VERSION "2021.24.4"

NS_ :

BS_:

BU_: VEH CH Receiver X

BA_DEF_ BO_ "GenMsgSendType" ENUM "Cyclic";
BA_DEF_ BO_ "GenMsgCycleTime" INT 0 10000;

BA_ "GenMsgSendType" BO_ 528 0;
BA_ "GenMsgCycleTime" BO_ 528 100;

BA_ "GenMsgSendType" BO_ 802 0;
BA_ "GenMsgCycleTime" BO_ 802 1000;

BA_ "GenMsgSendType" BO_ 12 0;
BA_ "GenMsgCycleTime" BO_ 12 1000;

BO_ 2007 DI_debug_7D7: 8 Vector__XXX
 SG_ DI_brakeSwitchNC m32 : 63|1@1+ (1,0) [0|0] "" Vector__XXX
 SG_ DI_immobilizerCondition m65 : 63|1@1+ (1,0) [0|0] "" Vector__XXX
 SG_ DI_brakeSwitchNO m32 : 62|1@1+ (1,0) [0|0] "" Vector__XXX
 SG_ DI_ONE_isRollingBackward m35 : 59|1@1+ (1,0) [0|0] "" Vector__XXX
 SG_ DI_ONE_quickBrakeBlendRequested m35 : 58|1@1+ (1,0) [0|0] "" Vector__XXX
 SG_ DI_ONE_slowBrakeBlendRequested m35 : 57|1@1+ (1,0) [0|0] "" Vector__XXX
 SG_ DI_ONE_vehicleHoldRequested m35 : 56|1@1+ (1,0) [0|0] "" Vector__XXX
 SG_ DI_immobilizerStack m68 : 56|8@1+ (0.4,0) [0|0] "" Vector__XXX
 SG_ DI_ssmState m32 : 56|4@1+ (1,0) [0|0] "" Vector__XXX
 SG_ DI_locCheckSpeedRef m75 : 54|8@1+ (1,0) [0|0] "" Vector__XXX
 SG_ DI_aebBlendOutActive m45 : 50|1@1+ (1,0) [0|0] "" Vector__XXX
 SG_ DI_ONE_ui m36 : 48|16@1- (0.5,0) [0|0] "" Vector__XXX
 SG_ DI_PED_zeroPedalTorque m38 : 48|16@1- (0.5,0) [0|0] "" Vector__XXX
 SG_ DI_module10HzStack m66 : 48|8@1+ (0.4,0) [0|0] "" Vector__XXX
 SG_ DI_pwrSatChargeCurrent m32 : 48|8@1+ (0.4,0) [0|0] "" Vector__XXX
 SG_ DI_tqScaleShift m33 : 48|8@1+ (0.4,0) [0|0] "" Vector__XXX
 SG_ DI_xcpStack m68 : 48|8@1+ (0.4,0) [0|0] "" Vector__XXX
 SG_ DI_brkStState m45 : 45|3@1+ (1,0) [0|0] "" Vector__XXX
 SG_ DI_ONE_zeroSpeedTorqueFwd m35 : 40|16@1- (0.5,0) [0|0] "" Vector__XXX
 SG_ DI_controlStack m67 : 40|8@1+ (0.4,0) [0|0] "" Vector__XXX
 SG_ DI_cpu10msMin m66 : 40|8@1+ (0.4,0) [0|0] "" Vector__XXX
 SG_ DI_opdUnavailableReason m45 : 40|5@1+ (1,0) [0|0] "" Vector__XXX
 SG_ DI_pwrSatDischargeCurrent m32 : 40|8@1+ (0.4,0) [0|0] "" Vector__XXX
 SG_ DI_sysStateExitCondition m34 : 40|5@1+ (1,0) [0|0] "" Vector__XXX
 SG_ DI_systemTorqueCommand m53 : 40|16@1- (0.5,0) [0|0] "" Vector__XXX
 SG_ DI_tqSatUiRegenTorque m33 : 40|8@1+ (0.4,0) [0|0] "" Vector__XXX
 SG_ DI_udsStack m68 : 40|8@1+ (0.4,0) [0|0] "" Vector__XXX
 SG_ DI_ONE_feedbackSpeedFilt m37 : 32|13@1+ (0.08,-40) [0|0] "" Vector__XXX
 SG_ DI_ONE_up m36 : 32|16@1- (0.5,0) [0|0] "" Vector__XXX
 SG_ DI_PED_noCruiseCommandPed m38 : 32|16@1- (0.5,0) [0|0] "" Vector__XXX
 SG_ DI_aebCancelReason m45 : 32|8@1+ (1,0) [0|0] "" Vector__XXX
 SG_ DI_cpu100HzAvg m66 : 32|8@1+ (0.4,0) [0|0] "" Vector__XXX
 SG_ DI_cpu20kHzAvg m67 : 32|8@1+ (0.4,0) [0|0] "" Vector__XXX
 SG_ DI_eepromStack m68 : 32|8@1+ (0.4,0) [0|0] "" Vector__XXX
 SG_ DI_pedalPosFilt m2 : 32|8@1+ (0.4,0) [0|0] "" Vector__XXX
 SG_ DI_pwrSatMinBusVoltage m32 : 32|8@1+ (0.4,0) [0|0] "" Vector__XXX
 SG_ DI_tqSatUiDriveTorque m33 : 32|8@1+ (0.4,0) [0|0] "" Vector__XXX
 SG_ DI_regenBackfillAbsSatState m39 : 26|2@1+ (1,0) [0|0] "" Vector__XXX
 SG_ DI_ONE_zeroPedalTorqueFwd m35 : 24|16@1- (0.5,0) [0|0] "" Vector__XXX
 SG_ DI_aebUnavailableReason m45 : 24|4@1+ (1,0) [0|0] "" Vector__XXX
 SG_ DI_cpu100HzMin m66 : 24|8@1+ (0.4,0) [0|0] "" Vector__XXX
 SG_ DI_cpu20kHzMin m67 : 24|8@1+ (0.4,0) [0|0] "" Vector__XXX
 SG_ DI_decodeHardwareStack m68 : 24|8@1+ (0.4,0) [0|0] "" Vector__XXX
 SG_ DI_pwrSatMaxBusVoltage m32 : 24|8@1+ (0.4,0) [0|0] "" Vector__XXX
 SG_ DI_sysPedalMaxTorque m34 : 24|15@1+ (0.5,0) [0|0] "" Vector__XXX
 SG_ DI_sysPostPedalMaxTorque m53 : 24|15@1+ (0.5,0) [0|0] "" Vector__XXX
 SG_ DI_regenBackfillUnavailableReaso m39 : 21|5@1+ (1,0) [0|0] "" Vector__XXX
 SG_ DI_veResForce m33 : 20|12@1- (0.0005,0) [0|0] "" Vector__XXX
 SG_ DI_ONE_feedbackTorquePed m36 : 16|16@1- (0.5,0) [0|0] "" Vector__XXX
 SG_ DI_ONE_targetSpeedFilt m37 : 16|13@1+ (0.08,-40) [0|0] "" Vector__XXX
 SG_ DI_PED_pedalTorqueFwd m38 : 16|16@1- (0.5,0) [0|0] "" Vector__XXX
 SG_ DI_aebFaultReason m45 : 16|4@1+ (1,0) [0|0] "" Vector__XXX
 SG_ DI_brakeCommandScale m2 : 16|9@1+ (0.02,0) [0|0] "" Vector__XXX
 SG_ DI_cpu10HzAvg m66 : 16|8@1+ (0.4,0) [0|0] "" Vector__XXX
 SG_ DI_cpu1kHzAvg m67 : 16|8@1+ (0.4,0) [0|0] "" Vector__XXX
 SG_ DI_idleStack m68 : 16|8@1+ (0.4,0) [0|0] "" Vector__XXX
 SG_ DI_pwrSatMaxRegenPower m32 : 16|8@1+ (0.4,0) [0|0] "" Vector__XXX
 SG_ DI_ONE_onePedalCommandFwd m35 : 8|16@1- (0.5,0) [0|0] "" Vector__XXX
 SG_ DI_cpu10HzMin m66 : 8|8@1+ (0.4,0) [0|0] "" Vector__XXX
 SG_ DI_cpu1kHzMin m67 : 8|8@1+ (0.4,0) [0|0] "" Vector__XXX
 SG_ DI_muSurfHigh m2 : 8|8@1+ (0.005,0) [0|0] "" Vector__XXX
 SG_ DI_pwrSatMaxDischargePower m32 : 8|8@1+ (0.4,0) [0|0] "" Vector__XXX
 SG_ DI_regenBackfillCmd m39 : 8|13@1+ (2,0) [0|0] "" Vector__XXX
 SG_ DI_sysHeatPowerOptimal m50 : 8|8@1+ (0.08,0) [0|0] "" Vector__XXX
 SG_ DI_sysPedalMinTorque m34 : 8|15@1+ (0.5,-13000) [0|0] "" Vector__XXX
 SG_ DI_sysPostPedalMinTorque m53 : 8|15@1+ (0.5,-13000) [0|0] "" Vector__XXX
 SG_ DI_systemStack m68 : 8|8@1+ (0.4,0) [0|0] "" Vector__XXX
 SG_ DI_veMassInvRaw m33 : 8|12@1+ (1e-07,0.0001) [0|0] "" Vector__XXX
 SG_ DI_debugSelector M : 0|8@1+ (1,0) [0|0] "" Vector__XXX

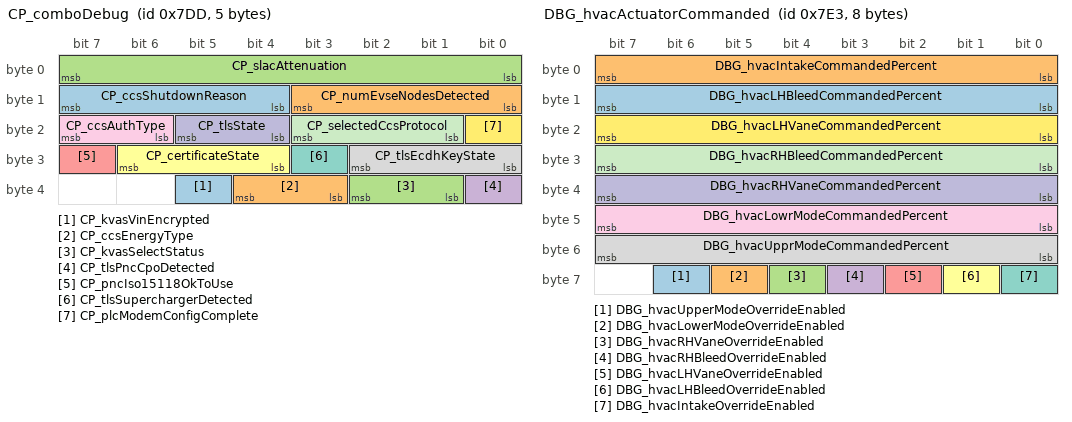
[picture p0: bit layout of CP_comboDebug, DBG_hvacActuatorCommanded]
BO_ 2013 CP_comboDebug: 5 Vector__XXX
 SG_ CP_kvasVinEncrypted : 37|1@1+ (1,0) [0|0] "" Vector__XXX
 SG_ CP_ccsEnergyType : 35|2@1+ (1,0) [0|0] "" Vector__XXX
 SG_ CP_kvasSelectStatus : 33|2@1+ (1,0) [0|0] "" Vector__XXX
 SG_ CP_tlsPncCpoDetected : 32|1@1+ (1,0) [0|0] "" Vector__XXX
 SG_ CP_pncIso15118OkToUse : 31|1@1+ (1,0) [0|0] "" Vector__XXX
 SG_ CP_certificateState : 28|3@1+ (1,0) [0|0] "" Vector__XXX
 SG_ CP_tlsSuperchargerDetected : 27|1@1+ (1,0) [0|0] "" Vector__XXX
 SG_ CP_tlsEcdhKeyState : 24|3@1+ (1,0) [0|0] "" Vector__XXX
 SG_ CP_ccsAuthType : 22|2@1+ (1,0) [0|0] "" Vector__XXX
 SG_ CP_tlsState : 20|2@1+ (1,0) [0|0] "" Vector__XXX
 SG_ CP_selectedCcsProtocol : 17|3@1+ (1,0) [0|0] "" Vector__XXX
 SG_ CP_plcModemConfigComplete : 16|1@1+ (1,0) [0|0] "" Vector__XXX
 SG_ CP_ccsShutdownReason : 12|4@1+ (1,0) [0|0] "" Vector__XXX
 SG_ CP_numEvseNodesDetected : 8|4@1+ (1,0) [0|0] "" Vector__XXX
 SG_ CP_slacAttenuation : 0|8@1+ (1,0) [0|0] "" Vector__XXX

BO_ 2014 UDS_functionalRequest_CH: 12 Vector__XXX
 SG_ UDS_functionalRequestDataCH : 7|64@0+ (1,0) [0|0] "" Vector__XXX

BO_ 2015 UDS_functionalRequest: 12 Vector__XXX
 SG_ UDS_functionalRequestData_7 : 63|8@0+ (1,0) [0|0] "" Vector__XXX
 SG_ UDS_functionalRequestData_6 : 55|8@0+ (1,0) [0|0] "" Vector__XXX
 SG_ UDS_functionalRequestData_5 : 47|8@0+ (1,0) [0|0] "" Vector__XXX
 SG_ UDS_functionalRequestData_4 : 39|8@0+ (1,0) [0|0] "" Vector__XXX
 SG_ UDS_functionalRequestData_3 : 31|8@0+ (1,0) [0|0] "" Vector__XXX
 SG_ UDS_functionalRequestData_2 : 23|8@0+ (1,0) [0|0] "" Vector__XXX
 SG_ UDS_functionalRequestData_1 : 15|8@0+ (1,0) [0|0] "" Vector__XXX
 SG_ UDS_functionalRequestData_0 : 7|8@0+ (1,0) [0|0] "" Vector__XXX

BO_ 2019 DBG_hvacActuatorCommanded: 8 Vector__XXX
 SG_ DBG_hvacUpperModeOverrideEnabled : 62|1@1+ (1,0) [0|0] "" Vector__XXX
 SG_ DBG_hvacLowerModeOverrideEnabled : 61|1@1+ (1,0) [0|0] "" Vector__XXX
 SG_ DBG_hvacRHVaneOverrideEnabled : 60|1@1+ (1,0) [0|0] "" Vector__XXX
 SG_ DBG_hvacRHBleedOverrideEnabled : 59|1@1+ (1,0) [0|0] "" Vector__XXX
 SG_ DBG_hvacLHVaneOverrideEnabled : 58|1@1+ (1,0) [0|0] "" Vector__XXX
 SG_ DBG_hvacLHBleedOverrideEnabled : 57|1@1+ (1,0) [0|0] "" Vector__XXX
 SG_ DBG_hvacIntakeOverrideEnabled : 56|1@1+ (1,0) [0|0] "" Vector__XXX
 SG_ DBG_hvacUpprModeCommandedPercent : 48|8@1+ (0.4,0) [0|0] "" Vector__XXX
 SG_ DBG_hvacLowrModeCommandedPercent : 40|8@1+ (0.4,0) [0|0] "" Vector__XXX
 SG_ DBG_hvacRHVaneCommandedPercent : 32|8@1+ (0.4,0) [0|0] "" Vector__XXX
 SG_ DBG_hvacRHBleedCommandedPercent : 24|8@1+ (0.4,0) [0|0] "" Vector__XXX
 SG_ DBG_hvacLHVaneCommandedPercent : 16|8@1+ (0.4,0) [0|0] "" Vector__XXX
 SG_ DBG_hvacLHBleedCommandedPercent : 8|8@1+ (0.4,0) [0|0] "" Vector__XXX
 SG_ DBG_hvacIntakeCommandedPercent : 0|8@1+ (0.4,0) [0|0] "" Vector__XXX

BO_ 2021 DIR_dlogData: 8 Vector__XXX
 SG_ DIR_dlogData : 0|64@1+ (1,0) [0|0] "" Vector__XXX

BO_ 2031 DBG_testMessage: 8 Vector__XXX
 SG_ DBG_testID : 0|16@1+ (1,0) [0|0] "" Vector__XXX

BO_ 2034 BMS_debugInfo_10Hz: 8 Vector__XXX
 SG_ BMS_verResourceRequest m29 : 58|2@1+ (1,0) [0|0] "" Vector__XXX
 SG_ BMS_bmsResourceRequest m29 : 56|2@1+ (1,0) [0|0] "" Vector__XXX
 SG_ BMS_dbgResistanceScaleChg m28 : 56|8@1+ (0.02,0) [0|0] "" Vector__XXX
 SG_ BMS_dbgResistanceScaleDch m27 : 56|8@1+ (0.02,0) [0|0] "" Vector__XXX
 SG_ BMS_cacUpdateError m18 : 54|9@1+ (0.2,0) [0|0] "" Vector__XXX
 SG_ BMS_hvpResourceRequest m29 : 54|2@1+ (1,0) [0|0] "" Vector__XXX
 SG_ BMS_refPointCacError2 m17 : 53|9@1+ (0.2,0) [0|0] "" Vector__XXX
 SG_ BMS_cacUpdateEndPoint m18 : 52|2@1+ (1,0) [0|0] "" Vector__XXX
 SG_ BMS_cpResourceRequest m29 : 52|2@1+ (1,0) [0|0] "" Vector__XXX
 SG_ BMS_cacUpdateStartPoint m18 : 50|2@1+ (1,0) [0|0] "" Vector__XXX
 SG_ BMS_ocvEstBrick1 m32 : 50|12@1+ (0.002,0) [0|0] "" Vector__XXX
 SG_ BMS_vehBusResourceRequest m29 : 50|2@1+ (1,0) [0|0] "" Vector__XXX
 SG_ BMS_hvsBusResourceRequest m29 : 48|2@1+ (1,0) [0|0] "" Vector__XXX
 SG_ BMS_cacUpdateCounter m18 : 47|3@1+ (1,0) [0|0] "" Vector__XXX
 SG_ BMS_hviBusResourceRequest m29 : 46|2@1+ (1,0) [0|0] "" Vector__XXX
 SG_ BMS_thmMdlDBG10 m13 : 46|10@1+ (0.1,-30) [0|0] "" Vector__XXX
 SG_ BMS_thmMdlDBG5 m12 : 46|10@1+ (0.1,-30) [0|0] "" Vector__XXX
 SG_ BMS_refPointCacError1 m17 : 44|9@1+ (0.2,0) [0|0] "" Vector__XXX
 SG_ BMS_sleepRequest m29 : 43|3@1+ (1,0) [0|0] "" Vector__XXX
 SG_ BMS_dbg1v5ReferenceHvp m21 : 40|16@1+ (0.001,0) [0|0] "" Vector__XXX
 SG_ BMS_dbgCapacitanceC2 m28 : 40|16@1+ (0.1,0) [0|0] "" Vector__XXX
 SG_ BMS_dbgCpFaultInputV m22 : 40|16@1+ (0.001,0) [0|0] "" Vector__XXX
 SG_ BMS_dbgCpLatchEnableV m25 : 40|16@1+ (0.001,0) [0|0] "" Vector__XXX
 SG_ BMS_dbgDcLinkCtrSenseCurrent m23 : 40|16@1+ (0.01,0) [0|0] "" Vector__XXX
 SG_ BMS_dbgHvilCoverVSense m24 : 40|16@1+ (0.001,0) [0|0] "" Vector__XXX
 SG_ BMS_dbgMaxCurrentDischarge m26 : 40|14@1+ (0.15,0) [0|0] "" Vector__XXX
 SG_ BMS_dbgResistanceR1 m27 : 40|16@1+ (0.001,0) [0|0] "" Vector__XXX
 SG_ BMS_packPositiveV m15 : 40|16@1- (0.02,0) [0|0] "" Vector__XXX
 SG_ BMS_restTime1 m20 : 40|15@1+ (0.1,0) [0|0] "" Vector__XXX
 SG_ BMS_sleepState m29 : 40|3@1+ (1,0) [0|0] "" Vector__XXX
 SG_ BMS_socRestingCurrentThreshold m3 : 40|12@1+ (0.001,0) [0|0] "" Vector__XXX
 SG_ BMS_isResting m3 : 39|1@1+ (1,0) [0|0] "" Vector__XXX
 SG_ BMS_ocvMaxBrick1 m32 : 38|12@1+ (0.002,0) [0|0] "" Vector__XXX
 SG_ BMS_cacInitialPtSocByOcv m18 : 37|10@1+ (0.1,0) [0|0] "" Vector__XXX
 SG_ BMS_thmMdlDBG4 m12 : 36|10@1+ (0.1,-30) [0|0] "" Vector__XXX
 SG_ BMS_thmMdlDBG9 m13 : 36|10@1+ (0.1,-30) [0|0] "" Vector__XXX
 SG_ BMS_refPointDeltaAhError m17 : 35|9@1- (0.05,0) [0|0] "" Vector__XXX
 SG_ BMS_verResourceState m29 : 35|3@1+ (1,0) [0|0] "" Vector__XXX
 SG_ BMS_ahDischarge m1 : 32|24@1+ (0.1,0) [0|0] "" Vector__XXX
 SG_ BMS_bmsResourceState m29 : 32|3@1+ (1,0) [0|0] "" Vector__XXX
 SG_ BMS_dbgBrick1OcvAccuracyBuffer m33 : 32|13@1+ (0.01,0) [0|0] "" Vector__XXX
 SG_ BMS_minBrickOcvIndex m3 : 32|7@1+ (1,0) [0|0] "" Vector__XXX
 SG_ BMS_cacEstimateBrick1 m18 : 27|10@1+ (0.5,75) [0|0] "" Vector__XXX
 SG_ BMS_pcsResourceState m29 : 27|3@1+ (1,0) [0|0] "" Vector__XXX
 SG_ BMS_dbgSocByOcvEst m16 : 26|10@1+ (0.1,0) [0|0] "" Vector__XXX
 SG_ BMS_ocvMinBrick1 m32 : 26|12@1+ (0.002,0) [0|0] "" Vector__XXX
 SG_ BMS_thmMdlDBG13 m14 : 26|10@1+ (0.1,-30) [0|0] "" Vector__XXX
 SG_ BMS_thmMdlDBG3 m12 : 26|10@1+ (0.1,-30) [0|0] "" Vector__XXX
 SG_ BMS_thmMdlDBG8 m13 : 26|10@1+ (0.1,-30) [0|0] "" Vector__XXX
 SG_ BMS_dbgStandbySupplyGood m30 : 25|1@1+ (1,0) [0|0] "" Vector__XXX
 SG_ BMS_dbg3v0ReferenceHvp m21 : 24|16@1+ (0.001,0) [0|0] "" Vector__XXX
 SG_ BMS_dbgCapacitanceC1 m28 : 24|16@1+ (0.1,0) [0|0] "" Vector__XXX
 SG_ BMS_dbgCpNegativeV m22 : 24|16@1- (0.02,0) [0|0] "" Vector__XXX
 SG_ BMS_dbgDcLinkNegativeV m23 : 24|16@1- (0.02,0) [0|0] "" Vector__XXX
 SG_ BMS_dbgFloodPortV2 m25 : 24|16@1+ (0.001,0) [0|0] "" Vector__XXX
 SG_ BMS_dbgInternalHvilSenseV m24 : 24|16@1+ (0.001,0) [0|0] "" Vector__XXX
 SG_ BMS_dbgMinLoadedVoltageDischarge m26 : 24|16@1+ (0.0001,0) [0|0] "" Vector__XXX
 SG_ BMS_dbgPolarizationVoltageV2 m27 : 24|16@1- (0.0001,0) [0|0] "" Vector__XXX
 SG_ BMS_dbgStandbySupplyEnabled m30 : 24|1@1+ (1,0) [0|0] "" Vector__XXX
 SG_ BMS_hvpResourceState m29 : 24|3@1+ (1,0) [0|0] "" Vector__XXX
 SG_ BMS_packNegativeV m15 : 24|16@1- (0.02,0) [0|0] "" Vector__XXX
 SG_ BMS_refPointDeltaAh m17 : 24|11@1- (0.5,0) [0|0] "" Vector__XXX
 SG_ BMS_stdCacError m19 : 24|8@1+ (0.2,0) [0|0] "" Vector__XXX
 SG_ BMS_stopSecondsElapsed m20 : 24|16@1+ (1,0) [0|0] "" Vector__XXX
 SG_ BMS_agedDischargePolarization m33 : 20|12@1+ (0.002,0) [0|0] "" Vector__XXX
 SG_ BMS_minBrickOcvMin m3 : 20|12@1+ (0.002,0) [0|0] "" Vector__XXX
 SG_ BMS_posIsolationSensorState m2 : 20|1@1+ (1,0) [0|0] "" Vector__XXX
 SG_ BMS_cacNetAhError m18 : 19|8@1+ (0.1,0) [0|0] "" Vector__XXX
 SG_ BMS_cpResourceState m29 : 19|3@1+ (1,0) [0|0] "" Vector__XXX
 SG_ BMS_maxSocByAhRawBrickId m32 : 19|7@1+ (1,1) [0|0] "" Vector__XXX
 SG_ BMS_negIsolationSensorState m2 : 19|1@1+ (1,0) [0|0] "" Vector__XXX
 SG_ BMS_dbgSocByOcvMin m16 : 16|10@1+ (0.1,0) [0|0] "" Vector__XXX
 SG_ BMS_positiveRIsoState m2 : 16|3@1+ (1,0) [0|0] "" Vector__XXX
 SG_ BMS_thmMdlDBG12 m14 : 16|10@1+ (0.1,-30) [0|0] "" Vector__XXX
 SG_ BMS_thmMdlDBG2 m12 : 16|10@1+ (0.1,-30) [0|0] "" Vector__XXX
 SG_ BMS_thmMdlDBG7 m13 : 16|10@1+ (0.1,-30) [0|0] "" Vector__XXX
 SG_ BMS_vehBusResourceState m29 : 16|3@1+ (1,0) [0|0] "" Vector__XXX
 SG_ BMS_refPointDeltaSoc m17 : 14|10@1+ (0.1,0) [0|0] "" Vector__XXX
 SG_ BMS_candidate2CacPointValid m17 : 13|1@1+ (1,0) [0|0] "" Vector__XXX
 SG_ BMS_candidate1CacPointValid m17 : 12|1@1+ (1,0) [0|0] "" Vector__XXX
 SG_ BMS_hvsBusResourceState m29 : 11|3@1+ (1,0) [0|0] "" Vector__XXX
 SG_ BMS_impedanceDevState m0 : 11|2@1+ (1,0) [0|0] "" Vector__XXX
 SG_ BMS_initialCacPointValid m17 : 11|1@1+ (1,0) [0|0] "" Vector__XXX
 SG_ BMS_negativeRIsoState m2 : 11|3@1+ (1,0) [0|0] "" Vector__XXX
 SG_ BMS_cacActivePoint m17 : 9|2@1+ (1,0) [0|0] "" Vector__XXX
 SG_ BMS_agedChargePolarization m33 : 8|12@1+ (0.002,0) [0|0] "" Vector__XXX
 SG_ BMS_ahCharge m1 : 8|24@1+ (0.1,0) [0|0] "" Vector__XXX
 SG_ BMS_avgCacError m19 : 8|9@1+ (0.2,0) [0|0] "" Vector__XXX
 SG_ BMS_brickRestingForCac m17 : 8|1@1+ (1,0) [0|0] "" Vector__XXX
 SG_ BMS_cacNetAhCounter m18 : 8|11@1- (1,0) [0|0] "" Vector__XXX
 SG_ BMS_dbg3v0ReferenceBms m21 : 8|16@1+ (0.001,0) [0|0] "" Vector__XXX
 SG_ BMS_dbgCpPositiveV m22 : 8|16@1- (0.02,0) [0|0] "" Vector__XXX
 SG_ BMS_dbgDcLinkPositiveV m23 : 8|16@1- (0.02,0) [0|0] "" Vector__XXX
 SG_ BMS_dbgFloodPortV1 m25 : 8|16@1+ (0.001,0) [0|0] "" Vector__XXX
 SG_ BMS_dbgMaxLoadedVoltageDischarge m26 : 8|16@1+ (0.0001,0) [0|0] "" Vector__XXX
 SG_ BMS_dbgPolarizationVoltageV1 m27 : 8|16@1- (0.0001,0) [0|0] "" Vector__XXX
 SG_ BMS_dbgResistanceR2 m28 : 8|16@1+ (0.001,0) [0|0] "" Vector__XXX
 SG_ BMS_dbgStandbySupplyOutV m30 : 8|16@1+ (0.001,0) [0|0] "" Vector__XXX
 SG_ BMS_dbgVerSenseV m24 : 8|16@1+ (0.001,0) [0|0] "" Vector__XXX
 SG_ BMS_driveBrickVoltageTarget m31 : 8|10@1+ (0.01,0) [0|0] "" Vector__XXX
 SG_ BMS_faultRetryCount m0 : 8|3@1+ (1,0) [0|0] "" Vector__XXX
 SG_ BMS_hviBusResourceState m29 : 8|3@1+ (1,0) [0|0] "" Vector__XXX
 SG_ BMS_isolationMode m2 : 8|3@1+ (1,0) [0|0] "" Vector__XXX
 SG_ BMS_maxSocByAhRaw m32 : 8|11@1+ (0.1,0) [0|0] "" Vector__XXX
 SG_ BMS_minBrickOcvMax m3 : 8|12@1+ (0.002,0) [0|0] "" Vector__XXX
 SG_ BMS_sumBrickVoltages m15 : 8|15@1+ (0.02,0) [0|0] "" Vector__XXX
 SG_ BMS_dbgPcsIsActiveOnHvs m0 : 7|1@1+ (1,0) [0|0] "" Vector__XXX
 SG_ BMS_allBricksRestingForCac m17 : 6|1@1+ (1,0) [0|0] "" Vector__XXX
 SG_ BMS_dbgPcsReportedOn m0 : 6|1@1+ (1,0) [0|0] "" Vector__XXX
 SG_ BMS_dbgSocByOcvMax m16 : 6|10@1+ (0.1,0) [0|0] "" Vector__XXX
 SG_ BMS_thmMdlDBG1 m12 : 6|10@1+ (0.1,-30) [0|0] "" Vector__XXX
 SG_ BMS_thmMdlDBG11 m14 : 6|10@1+ (0.1,-30) [0|0] "" Vector__XXX
 SG_ BMS_thmMdlDBG6 m13 : 6|10@1+ (0.1,-30) [0|0] "" Vector__XXX
 SG_ BMS_vshTestNeededTimer m20 : 6|18@1+ (1,0) [0|0] "" Vector__XXX
 SG_ BMS_10HzDebug_Id M : 0|6@1+ (1,0) [0|0] "" Vector__XXX

BO_ 2036 GTW_canLogAvailability: 1 Vector__XXX
 SG_ GTW_canLogServiceAvailability : 0|2@1+ (1,0) [0|0] "" Vector__XXX

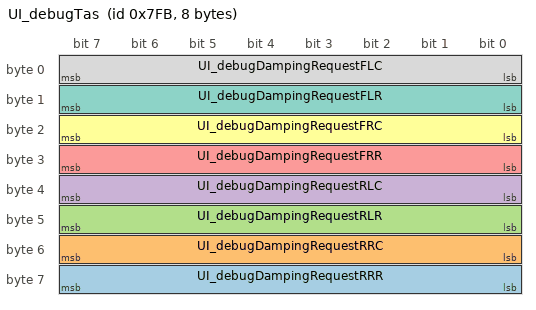
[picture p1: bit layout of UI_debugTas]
BO_ 2043 UI_debugTas: 8 Vector__XXX
 SG_ UI_debugDampingRequestRRR : 56|8@1+ (0.01,0) [0|0] "" Vector__XXX
 SG_ UI_debugDampingRequestRRC : 48|8@1+ (0.01,0) [0|0] "" Vector__XXX
 SG_ UI_debugDampingRequestRLR : 40|8@1+ (0.01,0) [0|0] "" Vector__XXX
 SG_ UI_debugDampingRequestRLC : 32|8@1+ (0.01,0) [0|0] "" Vector__XXX
 SG_ UI_debugDampingRequestFRR : 24|8@1+ (0.01,0) [0|0] "" Vector__XXX
 SG_ UI_debugDampingRequestFRC : 16|8@1+ (0.01,0) [0|0] "" Vector__XXX
 SG_ UI_debugDampingRequestFLR : 8|8@1+ (0.01,0) [0|0] "" Vector__XXX
 SG_ UI_debugDampingRequestFLC : 0|8@1+ (0.01,0) [0|0] "" Vector__XXX

BO_ 2046 PCS2_DRLog: 8 Vector__XXX
 SG_ PCS2_DRLog_CPU0_PlotId m1 : 48|8@1+ (1,0) [0|0] "" Vector__XXX
 SG_ PCS2_DRLog_CPU1_PlotId m11 : 48|8@1+ (1,0) [0|0] "" Vector__XXX
 SG_ PCS2_DRLog_CPU2_PlotId m21 : 48|8@1+ (1,0) [0|0] "" Vector__XXX
 SG_ PCS2_DRLog_CPU3_PlotId m31 : 48|8@1+ (1,0) [0|0] "" Vector__XXX
 SG_ PCS2_DRLog_CPU0_InstanceTriggerA m3 : 40|16@1+ (1,0) [0|0] "" Vector__XXX
 SG_ PCS2_DRLog_CPU1_InstanceTriggerA m13 : 40|16@1+ (1,0) [0|0] "" Vector__XXX
 SG_ PCS2_DRLog_CPU2_InstanceTriggerA m23 : 40|16@1+ (1,0) [0|0] "" Vector__XXX
 SG_ PCS2_DRLog_CPU3_InstanceTriggerA m33 : 40|16@1+ (1,0) [0|0] "" Vector__XXX
 SG_ PCS2_DRLog_CPU0_Sample m2 : 32|32@1- (0.001,0) [0|0] "" Vector__XXX
 SG_ PCS2_DRLog_CPU0_Sample_10V0_rail m170 : 32|32@1- (0.001,0) [0|0] "" Vector__XXX
 SG_ PCS2_DRLog_CPU0_Sample_18V0_LLC_ m118 : 32|32@1- (0.001,0) [0|0] "" Vector__XXX
 SG_ PCS2_DRLog_CPU0_Sample_18V0_Volt m117 : 32|32@1- (0.001,0) [0|0] "" Vector__XXX
 SG_ PCS2_DRLog_CPU0_Sample_18V0_boos m160 : 32|32@1- (0.001,0) [0|0] "" Vector__XXX
 SG_ PCS2_DRLog_CPU0_Sample_18V0_buck m169 : 32|32@1- (0.001,0) [0|0] "" Vector__XXX
 SG_ PCS2_DRLog_CPU0_Sample_1V6_ref_v m172 : 32|32@1- (0.001,0) [0|0] "" Vector__XXX
 SG_ PCS2_DRLog_CPU0_Sample_4V5_rail_ m171 : 32|32@1- (0.001,0) [0|0] "" Vector__XXX
 SG_ PCS2_DRLog_CPU0_Sample_boost_buc m174 : 32|32@1- (0.001,0) [0|0] "" Vector__XXX
 SG_ PCS2_DRLog_CPU0_Sample_boost_ise m173 : 32|32@1- (0.001,0) [0|0] "" Vector__XXX
 SG_ PCS2_DRLog_CPU0_Sample_boos_0000 m175 : 32|32@1- (0.001,0) [0|0] "" Vector__XXX
 SG_ PCS2_DRLog_CPU0_Sample_burst_mod m158 : 32|32@1- (0.001,0) [0|0] "" Vector__XXX
 SG_ PCS2_DRLog_CPU0_Sample_channel8 m119 : 32|32@1- (0.001,0) [0|0] "" Vector__XXX
 SG_ PCS2_DRLog_CPU0_Sample_dcdc_vHv m163 : 32|32@1- (0.001,0) [0|0] "" Vector__XXX
 SG_ PCS2_DRLog_CPU0_Sample_dcdc_vHv_ m116 : 32|32@1- (0.001,0) [0|0] "" Vector__XXX
 SG_ PCS2_DRLog_CPU0_Sample_dcdc_0000 m102 : 32|32@1- (0.001,0) [0|0] "" Vector__XXX
 SG_ PCS2_DRLog_CPU0_Sample_dcdc_vLv m103 : 32|32@1- (0.001,0) [0|0] "" Vector__XXX
 SG_ PCS2_DRLog_CPU0_Sample_freq m112 : 32|32@1- (0.001,0) [0|0] "" Vector__XXX
 SG_ PCS2_DRLog_CPU0_Sample_half_bus_ m113 : 32|32@1- (0.001,0) [0|0] "" Vector__XXX
 SG_ PCS2_DRLog_CPU0_Sample_half_peri m100 : 32|32@1- (0.001,0) [0|0] "" Vector__XXX
 SG_ PCS2_DRLog_CPU0_Sample_i_HV_cl_s m115 : 32|32@1- (0.001,0) [0|0] "" Vector__XXX
 SG_ PCS2_DRLog_CPU0_Sample_i_HV_0000 m114 : 32|32@1- (0.001,0) [0|0] "" Vector__XXX
 SG_ PCS2_DRLog_CPU0_Sample_i_HV_cmd m101 : 32|32@1- (0.001,0) [0|0] "" Vector__XXX
 SG_ PCS2_DRLog_CPU0_Sample_itank m104 : 32|32@1- (0.001,0) [0|0] "" Vector__XXX
 SG_ PCS2_DRLog_CPU0_Sample_itank_mar m109 : 32|32@1- (0.001,0) [0|0] "" Vector__XXX
 SG_ PCS2_DRLog_CPU0_Sample_shrt_marg m108 : 32|32@1- (0.001,0) [0|0] "" Vector__XXX
 SG_ PCS2_DRLog_CPU0_Sample_shrt_0000 m107 : 32|32@1- (0.001,0) [0|0] "" Vector__XXX
 SG_ PCS2_DRLog_CPU0_Sample_theta_HV m110 : 32|32@1- (0.001,0) [0|0] "" Vector__XXX
 SG_ PCS2_DRLog_CPU0_Sample_theta_LV m111 : 32|32@1- (0.001,0) [0|0] "" Vector__XXX
 SG_ PCS2_DRLog_CPU0_Sample_zcd_flt_c m105 : 32|32@1- (0.001,0) [0|0] "" Vector__XXX
 SG_ PCS2_DRLog_CPU0_Sample_zcd_fltd m106 : 32|32@1- (0.001,0) [0|0] "" Vector__XXX
 SG_ PCS2_DRLog_CPU0_Sample_zcd_risin m165 : 32|32@1- (0.001,0) [0|0] "" Vector__XXX
 SG_ PCS2_DRLog_CPU1_Sample m12 : 32|32@1- (0.001,0) [0|0] "" Vector__XXX
 SG_ PCS2_DRLog_CPU1_Sample_18V0_LLC_ m138 : 32|32@1- (0.001,0) [0|0] "" Vector__XXX
 SG_ PCS2_DRLog_CPU1_Sample_18V0_Volt m137 : 32|32@1- (0.001,0) [0|0] "" Vector__XXX
 SG_ PCS2_DRLog_CPU1_Sample_18V0_boos m161 : 32|32@1- (0.001,0) [0|0] "" Vector__XXX
 SG_ PCS2_DRLog_CPU1_Sample_burst_mod m159 : 32|32@1- (0.001,0) [0|0] "" Vector__XXX
 SG_ PCS2_DRLog_CPU1_Sample_dcdc_iHv m139 : 32|32@1- (0.001,0) [0|0] "" Vector__XXX
 SG_ PCS2_DRLog_CPU1_Sample_dcdc_vHv m164 : 32|32@1- (0.001,0) [0|0] "" Vector__XXX
 SG_ PCS2_DRLog_CPU1_Sample_dcdc_vHv_ m123 : 32|32@1- (0.001,0) [0|0] "" Vector__XXX
 SG_ PCS2_DRLog_CPU1_Sample_dcdc_0000 m126 : 32|32@1- (0.001,0) [0|0] "" Vector__XXX
 SG_ PCS2_DRLog_CPU1_Sample_dcdc_vLv m127 : 32|32@1- (0.001,0) [0|0] "" Vector__XXX
 SG_ PCS2_DRLog_CPU1_Sample_freq m136 : 32|32@1- (0.001,0) [0|0] "" Vector__XXX
 SG_ PCS2_DRLog_CPU1_Sample_half_bus_ m120 : 32|32@1- (0.001,0) [0|0] "" Vector__XXX
 SG_ PCS2_DRLog_CPU1_Sample_half_peri m124 : 32|32@1- (0.001,0) [0|0] "" Vector__XXX
 SG_ PCS2_DRLog_CPU1_Sample_i_HV_cl_s m122 : 32|32@1- (0.001,0) [0|0] "" Vector__XXX
 SG_ PCS2_DRLog_CPU1_Sample_i_HV_0000 m121 : 32|32@1- (0.001,0) [0|0] "" Vector__XXX
 SG_ PCS2_DRLog_CPU1_Sample_i_HV_cmd m125 : 32|32@1- (0.001,0) [0|0] "" Vector__XXX
 SG_ PCS2_DRLog_CPU1_Sample_itank m128 : 32|32@1- (0.001,0) [0|0] "" Vector__XXX
 SG_ PCS2_DRLog_CPU1_Sample_itank_mar m133 : 32|32@1- (0.001,0) [0|0] "" Vector__XXX
 SG_ PCS2_DRLog_CPU1_Sample_shrt_marg m132 : 32|32@1- (0.001,0) [0|0] "" Vector__XXX
 SG_ PCS2_DRLog_CPU1_Sample_shrt_0000 m131 : 32|32@1- (0.001,0) [0|0] "" Vector__XXX
 SG_ PCS2_DRLog_CPU1_Sample_theta_HV m134 : 32|32@1- (0.001,0) [0|0] "" Vector__XXX
 SG_ PCS2_DRLog_CPU1_Sample_theta_LV m135 : 32|32@1- (0.001,0) [0|0] "" Vector__XXX
 SG_ PCS2_DRLog_CPU1_Sample_zcd_flt_c m129 : 32|32@1- (0.001,0) [0|0] "" Vector__XXX
 SG_ PCS2_DRLog_CPU1_Sample_zcd_fltd m130 : 32|32@1- (0.001,0) [0|0] "" Vector__XXX
 SG_ PCS2_DRLog_CPU1_Sample_zcd_risin m166 : 32|32@1- (0.001,0) [0|0] "" Vector__XXX
 SG_ PCS2_DRLog_CPU2_Sample m22 : 32|32@1- (0.001,0) [0|0] "" Vector__XXX
 SG_ PCS2_DRLog_CPU3_Sample m32 : 32|32@1- (0.001,0) [0|0] "" Vector__XXX
 SG_ PCS2_DRLog_CPU3_Sample_18V0_LLC_ m157 : 32|32@1- (0.001,0) [0|0] "" Vector__XXX
 SG_ PCS2_DRLog_CPU3_Sample_18V0_Volt m156 : 32|32@1- (0.001,0) [0|0] "" Vector__XXX
 SG_ PCS2_DRLog_CPU3_Sample_18V0_boos m162 : 32|32@1- (0.001,0) [0|0] "" Vector__XXX
 SG_ PCS2_DRLog_CPU3_Sample_Itank_mar m144 : 32|32@1- (0.001,0) [0|0] "" Vector__XXX
 SG_ PCS2_DRLog_CPU3_Sample_freq m151 : 32|32@1- (0.001,0) [0|0] "" Vector__XXX
 SG_ PCS2_DRLog_CPU3_Sample_hvdc_curr m155 : 32|32@1- (0.001,0) [0|0] "" Vector__XXX
 SG_ PCS2_DRLog_CPU3_Sample_i_ac_cmd_ m148 : 32|32@1- (0.001,0) [0|0] "" Vector__XXX
 SG_ PCS2_DRLog_CPU3_Sample_i_ac_0000 m149 : 32|32@1- (0.001,0) [0|0] "" Vector__XXX
 SG_ PCS2_DRLog_CPU3_Sample_i_ac_0001 m153 : 32|32@1- (0.001,0) [0|0] "" Vector__XXX
 SG_ PCS2_DRLog_CPU3_Sample_i_ac_ref_ m147 : 32|32@1- (0.001,0) [0|0] "" Vector__XXX
 SG_ PCS2_DRLog_CPU3_Sample_i_ln_l1 m142 : 32|32@1- (0.001,0) [0|0] "" Vector__XXX
 SG_ PCS2_DRLog_CPU3_Sample_i_ln_l2 m143 : 32|32@1- (0.001,0) [0|0] "" Vector__XXX
 SG_ PCS2_DRLog_CPU3_Sample_i_ln_l3 m154 : 32|32@1- (0.001,0) [0|0] "" Vector__XXX
 SG_ PCS2_DRLog_CPU3_Sample_itank_pea m150 : 32|32@1- (0.001,0) [0|0] "" Vector__XXX
 SG_ PCS2_DRLog_CPU3_Sample_pwm_enabl m145 : 32|32@1- (0.001,0) [0|0] "" Vector__XXX
 SG_ PCS2_DRLog_CPU3_Sample_v_dc m152 : 32|32@1- (0.001,0) [0|0] "" Vector__XXX
 SG_ PCS2_DRLog_CPU3_Sample_v_ln_l1 m140 : 32|32@1- (0.001,0) [0|0] "" Vector__XXX
 SG_ PCS2_DRLog_CPU3_Sample_v_ln_l2 m141 : 32|32@1- (0.001,0) [0|0] "" Vector__XXX
 SG_ PCS2_DRLog_CPU3_Sample_v_ln_l3 m146 : 32|32@1- (0.001,0) [0|0] "" Vector__XXX
 SG_ PCS2_DRLog_CPU3_Sample_v_ln_pre_ m167 : 32|32@1- (0.001,0) [0|0] "" Vector__XXX
 SG_ PCS2_DRLog_CPU3_Sample_v_ln_0000 m168 : 32|32@1- (0.001,0) [0|0] "" Vector__XXX
 SG_ PCS2_DRLog_CPU0_InstanceBufferPo m3 : 24|16@1+ (1,0) [0|0] "" Vector__XXX
 SG_ PCS2_DRLog_CPU1_InstanceBufferPo m13 : 24|16@1+ (1,0) [0|0] "" Vector__XXX
 SG_ PCS2_DRLog_CPU2_InstanceBufferPo m23 : 24|16@1+ (1,0) [0|0] "" Vector__XXX
 SG_ PCS2_DRLog_CPU3_InstanceBufferPo m33 : 24|16@1+ (1,0) [0|0] "" Vector__XXX
 SG_ PCS2_DRLog_CPU0_Index m2 : 16|16@1+ (1,0) [0|0] "" Vector__XXX
 SG_ PCS2_DRLog_CPU0_Index_10V0_rail_ m170 : 16|16@1+ (1,0) [0|0] "" Vector__XXX
 SG_ PCS2_DRLog_CPU0_Index_18V0_LLC_F m118 : 16|16@1+ (1,0) [0|0] "" Vector__XXX
 SG_ PCS2_DRLog_CPU0_Index_18V0_Volta m117 : 16|16@1+ (1,0) [0|0] "" Vector__XXX
 SG_ PCS2_DRLog_CPU0_Index_18V0_boost m160 : 16|16@1+ (1,0) [0|0] "" Vector__XXX
 SG_ PCS2_DRLog_CPU0_Index_18V0_buck_ m169 : 16|16@1+ (1,0) [0|0] "" Vector__XXX
 SG_ PCS2_DRLog_CPU0_Index_1V6_ref_vs m172 : 16|16@1+ (1,0) [0|0] "" Vector__XXX
 SG_ PCS2_DRLog_CPU0_Index_4V5_rail_v m171 : 16|16@1+ (1,0) [0|0] "" Vector__XXX
 SG_ PCS2_DRLog_CPU0_Index_boost_buck m174 : 16|16@1+ (1,0) [0|0] "" Vector__XXX
 SG_ PCS2_DRLog_CPU0_Index_boost_isen m173 : 16|16@1+ (1,0) [0|0] "" Vector__XXX
 SG_ PCS2_DRLog_CPU0_Index_boost_0000 m175 : 16|16@1+ (1,0) [0|0] "" Vector__XXX
 SG_ PCS2_DRLog_CPU0_Index_burst_mode m158 : 16|16@1+ (1,0) [0|0] "" Vector__XXX
 SG_ PCS2_DRLog_CPU0_Index_channel8 m119 : 16|16@1+ (1,0) [0|0] "" Vector__XXX
 SG_ PCS2_DRLog_CPU0_Index_dcdc_vHv m163 : 16|16@1+ (1,0) [0|0] "" Vector__XXX
 SG_ PCS2_DRLog_CPU0_Index_dcdc_vHv_b m116 : 16|16@1+ (1,0) [0|0] "" Vector__XXX
 SG_ PCS2_DRLog_CPU0_Index_dcdc_vHv_t m102 : 16|16@1+ (1,0) [0|0] "" Vector__XXX
 SG_ PCS2_DRLog_CPU0_Index_dcdc_vLv m103 : 16|16@1+ (1,0) [0|0] "" Vector__XXX
 SG_ PCS2_DRLog_CPU0_Index_freq m112 : 16|16@1+ (1,0) [0|0] "" Vector__XXX
 SG_ PCS2_DRLog_CPU0_Index_half_bus_c m113 : 16|16@1+ (1,0) [0|0] "" Vector__XXX
 SG_ PCS2_DRLog_CPU0_Index_half_perio m100 : 16|16@1+ (1,0) [0|0] "" Vector__XXX
 SG_ PCS2_DRLog_CPU0_Index_i_HV_cl_si m115 : 16|16@1+ (1,0) [0|0] "" Vector__XXX
 SG_ PCS2_DRLog_CPU0_Index_i_HV_cl_so m114 : 16|16@1+ (1,0) [0|0] "" Vector__XXX
 SG_ PCS2_DRLog_CPU0_Index_i_HV_cmd m101 : 16|16@1+ (1,0) [0|0] "" Vector__XXX
 SG_ PCS2_DRLog_CPU0_Index_itank m104 : 16|16@1+ (1,0) [0|0] "" Vector__XXX
 SG_ PCS2_DRLog_CPU0_Index_itank_marg m109 : 16|16@1+ (1,0) [0|0] "" Vector__XXX
 SG_ PCS2_DRLog_CPU0_Index_shrt_margi m108 : 16|16@1+ (1,0) [0|0] "" Vector__XXX
 SG_ PCS2_DRLog_CPU0_Index_shrt__0000 m107 : 16|16@1+ (1,0) [0|0] "" Vector__XXX
 SG_ PCS2_DRLog_CPU0_Index_theta_HV m110 : 16|16@1+ (1,0) [0|0] "" Vector__XXX
 SG_ PCS2_DRLog_CPU0_Index_theta_LV m111 : 16|16@1+ (1,0) [0|0] "" Vector__XXX
 SG_ PCS2_DRLog_CPU0_Index_zcd_flt_cn m105 : 16|16@1+ (1,0) [0|0] "" Vector__XXX
 SG_ PCS2_DRLog_CPU0_Index_zcd_fltd m106 : 16|16@1+ (1,0) [0|0] "" Vector__XXX
 SG_ PCS2_DRLog_CPU0_Index_zcd_rising m165 : 16|16@1+ (1,0) [0|0] "" Vector__XXX
 SG_ PCS2_DRLog_CPU0_InstanceIndex m3 : 16|4@1+ (1,0) [0|0] "" Vector__XXX
 SG_ PCS2_DRLog_CPU0_SampleFrequency m1 : 16|32@1+ (1,0) [0|0] "" Vector__XXX
 SG_ PCS2_DRLog_CPU1_Index m12 : 16|16@1+ (1,0) [0|0] "" Vector__XXX
 SG_ PCS2_DRLog_CPU1_Index_18V0_LLC_F m138 : 16|16@1+ (1,0) [0|0] "" Vector__XXX
 SG_ PCS2_DRLog_CPU1_Index_18V0_Volta m137 : 16|16@1+ (1,0) [0|0] "" Vector__XXX
 SG_ PCS2_DRLog_CPU1_Index_18V0_boost m161 : 16|16@1+ (1,0) [0|0] "" Vector__XXX
 SG_ PCS2_DRLog_CPU1_Index_burst_mode m159 : 16|16@1+ (1,0) [0|0] "" Vector__XXX
 SG_ PCS2_DRLog_CPU1_Index_dcdc_iHv m139 : 16|16@1+ (1,0) [0|0] "" Vector__XXX
 SG_ PCS2_DRLog_CPU1_Index_dcdc_vHv m164 : 16|16@1+ (1,0) [0|0] "" Vector__XXX
 SG_ PCS2_DRLog_CPU1_Index_dcdc_vHv_b m123 : 16|16@1+ (1,0) [0|0] "" Vector__XXX
 SG_ PCS2_DRLog_CPU1_Index_dcdc_vHv_t m126 : 16|16@1+ (1,0) [0|0] "" Vector__XXX
 SG_ PCS2_DRLog_CPU1_Index_dcdc_vLv m127 : 16|16@1+ (1,0) [0|0] "" Vector__XXX
 SG_ PCS2_DRLog_CPU1_Index_freq m136 : 16|16@1+ (1,0) [0|0] "" Vector__XXX
 SG_ PCS2_DRLog_CPU1_Index_half_bus_c m120 : 16|16@1+ (1,0) [0|0] "" Vector__XXX
 SG_ PCS2_DRLog_CPU1_Index_half_perio m124 : 16|16@1+ (1,0) [0|0] "" Vector__XXX
 SG_ PCS2_DRLog_CPU1_Index_i_HV_cl_si m122 : 16|16@1+ (1,0) [0|0] "" Vector__XXX
 SG_ PCS2_DRLog_CPU1_Index_i_HV_cl_so m121 : 16|16@1+ (1,0) [0|0] "" Vector__XXX
 SG_ PCS2_DRLog_CPU1_Index_i_HV_cmd m125 : 16|16@1+ (1,0) [0|0] "" Vector__XXX
 SG_ PCS2_DRLog_CPU1_Index_itank m128 : 16|16@1+ (1,0) [0|0] "" Vector__XXX
 SG_ PCS2_DRLog_CPU1_Index_itank_marg m133 : 16|16@1+ (1,0) [0|0] "" Vector__XXX
 SG_ PCS2_DRLog_CPU1_Index_shrt_margi m132 : 16|16@1+ (1,0) [0|0] "" Vector__XXX
 SG_ PCS2_DRLog_CPU1_Index_shrt__0000 m131 : 16|16@1+ (1,0) [0|0] "" Vector__XXX
 SG_ PCS2_DRLog_CPU1_Index_theta_HV m134 : 16|16@1+ (1,0) [0|0] "" Vector__XXX
 SG_ PCS2_DRLog_CPU1_Index_theta_LV m135 : 16|16@1+ (1,0) [0|0] "" Vector__XXX
 SG_ PCS2_DRLog_CPU1_Index_zcd_flt_cn m129 : 16|16@1+ (1,0) [0|0] "" Vector__XXX
 SG_ PCS2_DRLog_CPU1_Index_zcd_fltd m130 : 16|16@1+ (1,0) [0|0] "" Vector__XXX
 SG_ PCS2_DRLog_CPU1_Index_zcd_rising m166 : 16|16@1+ (1,0) [0|0] "" Vector__XXX
 SG_ PCS2_DRLog_CPU1_InstanceIndex m13 : 16|4@1+ (1,0) [0|0] "" Vector__XXX
 SG_ PCS2_DRLog_CPU1_SampleFrequency m11 : 16|32@1+ (1,0) [0|0] "" Vector__XXX
 SG_ PCS2_DRLog_CPU2_Index m22 : 16|16@1+ (1,0) [0|0] "" Vector__XXX
 SG_ PCS2_DRLog_CPU2_InstanceIndex m23 : 16|4@1+ (1,0) [0|0] "" Vector__XXX
 SG_ PCS2_DRLog_CPU2_SampleFrequency m21 : 16|32@1+ (1,0) [0|0] "" Vector__XXX
 SG_ PCS2_DRLog_CPU3_Index m32 : 16|16@1+ (1,0) [0|0] "" Vector__XXX
 SG_ PCS2_DRLog_CPU3_Index_18V0_LLC_F m157 : 16|16@1+ (1,0) [0|0] "" Vector__XXX
 SG_ PCS2_DRLog_CPU3_Index_18V0_Volta m156 : 16|16@1+ (1,0) [0|0] "" Vector__XXX
 SG_ PCS2_DRLog_CPU3_Index_18V0_boost m162 : 16|16@1+ (1,0) [0|0] "" Vector__XXX
 SG_ PCS2_DRLog_CPU3_Index_Itank_marg m144 : 16|16@1+ (1,0) [0|0] "" Vector__XXX
 SG_ PCS2_DRLog_CPU3_Index_freq m151 : 16|16@1+ (1,0) [0|0] "" Vector__XXX
 SG_ PCS2_DRLog_CPU3_Index_hvdc_curre m155 : 16|16@1+ (1,0) [0|0] "" Vector__XXX
 SG_ PCS2_DRLog_CPU3_Index_i_ac_cmd_l m148 : 16|16@1+ (1,0) [0|0] "" Vector__XXX
 SG_ PCS2_DRLog_CPU3_Index_i_ac__0000 m149 : 16|16@1+ (1,0) [0|0] "" Vector__XXX
 SG_ PCS2_DRLog_CPU3_Index_i_ac__0001 m153 : 16|16@1+ (1,0) [0|0] "" Vector__XXX
 SG_ PCS2_DRLog_CPU3_Index_i_ac_ref_l m147 : 16|16@1+ (1,0) [0|0] "" Vector__XXX
 SG_ PCS2_DRLog_CPU3_Index_i_ln_l1 m142 : 16|16@1+ (1,0) [0|0] "" Vector__XXX
 SG_ PCS2_DRLog_CPU3_Index_i_ln_l2 m143 : 16|16@1+ (1,0) [0|0] "" Vector__XXX
 SG_ PCS2_DRLog_CPU3_Index_i_ln_l3 m154 : 16|16@1+ (1,0) [0|0] "" Vector__XXX
 SG_ PCS2_DRLog_CPU3_Index_itank_peak m150 : 16|16@1+ (1,0) [0|0] "" Vector__XXX
 SG_ PCS2_DRLog_CPU3_Index_pwm_enable m145 : 16|16@1+ (1,0) [0|0] "" Vector__XXX
 SG_ PCS2_DRLog_CPU3_Index_v_dc m152 : 16|16@1+ (1,0) [0|0] "" Vector__XXX
 SG_ PCS2_DRLog_CPU3_Index_v_ln_l1 m140 : 16|16@1+ (1,0) [0|0] "" Vector__XXX
 SG_ PCS2_DRLog_CPU3_Index_v_ln_l2 m141 : 16|16@1+ (1,0) [0|0] "" Vector__XXX
 SG_ PCS2_DRLog_CPU3_Index_v_ln_l3 m146 : 16|16@1+ (1,0) [0|0] "" Vector__XXX
 SG_ PCS2_DRLog_CPU3_Index_v_ln_pre_r m167 : 16|16@1+ (1,0) [0|0] "" Vector__XXX
 SG_ PCS2_DRLog_CPU3_Index_v_ln__0000 m168 : 16|16@1+ (1,0) [0|0] "" Vector__XXX
 SG_ PCS2_DRLog_CPU3_InstanceIndex m33 : 16|4@1+ (1,0) [0|0] "" Vector__XXX
 SG_ PCS2_DRLog_CPU3_SampleFrequency m31 : 16|32@1+ (1,0) [0|0] "" Vector__XXX
 SG_ PCS2_DRLog_CPU0_ServiceState m3 : 10|4@1+ (1,0) [0|0] "" Vector__XXX
 SG_ PCS2_DRLog_CPU1_ServiceState m13 : 10|4@1+ (1,0) [0|0] "" Vector__XXX
 SG_ PCS2_DRLog_CPU2_ServiceState m23 : 10|4@1+ (1,0) [0|0] "" Vector__XXX
 SG_ PCS2_DRLog_CPU3_ServiceState m33 : 10|4@1+ (1,0) [0|0] "" Vector__XXX
 SG_ PCS2_DRLog_CPU0_Triggered m3 : 9|1@1+ (1,0) [0|0] "" Vector__XXX
 SG_ PCS2_DRLog_CPU1_Triggered m13 : 9|1@1+ (1,0) [0|0] "" Vector__XXX
 SG_ PCS2_DRLog_CPU2_Triggered m23 : 9|1@1+ (1,0) [0|0] "" Vector__XXX
 SG_ PCS2_DRLog_CPU3_Triggered m33 : 9|1@1+ (1,0) [0|0] "" Vector__XXX
 SG_ PCS2_DRLog_CPU0_DlogClientConnec m3 : 8|1@1+ (1,0) [0|0] "" Vector__XXX
 SG_ PCS2_DRLog_CPU0_Postamble m4 : 8|56@1+ (1,0) [0|0] "" Vector__XXX
 SG_ PCS2_DRLog_CPU0_Preamble m0 : 8|56@1+ (1,0) [0|0] "" Vector__XXX
 SG_ PCS2_DRLog_CPU0_SampleRate m2 : 8|8@1+ (1,0) [0|0] "" Vector__XXX
 SG_ PCS2_DRLog_CPU0_SampleRate_10V0_ m170 : 8|8@1+ (1,0) [0|0] "" Vector__XXX
 SG_ PCS2_DRLog_CPU0_SampleRate__0005 m118 : 8|8@1+ (1,0) [0|0] "" Vector__XXX
 SG_ PCS2_DRLog_CPU0_SampleRate_18V0_ m117 : 8|8@1+ (1,0) [0|0] "" Vector__XXX
 SG_ PCS2_DRLog_CPU0_SampleRate__0008 m160 : 8|8@1+ (1,0) [0|0] "" Vector__XXX
 SG_ PCS2_DRLog_CPU0_SampleRate__0006 m169 : 8|8@1+ (1,0) [0|0] "" Vector__XXX
 SG_ PCS2_DRLog_CPU0_SampleRate_1V6_r m172 : 8|8@1+ (1,0) [0|0] "" Vector__XXX
 SG_ PCS2_DRLog_CPU0_SampleRate_4V5_r m171 : 8|8@1+ (1,0) [0|0] "" Vector__XXX
 SG_ PCS2_DRLog_CPU0_SampleRate_boost m173 : 8|8@1+ (1,0) [0|0] "" Vector__XXX
 SG_ PCS2_DRLog_CPU0_SampleRate__0013 m175 : 8|8@1+ (1,0) [0|0] "" Vector__XXX
 SG_ PCS2_DRLog_CPU0_SampleRate_buck_ m174 : 8|8@1+ (1,0) [0|0] "" Vector__XXX
 SG_ PCS2_DRLog_CPU0_SampleRate_burst m158 : 8|8@1+ (1,0) [0|0] "" Vector__XXX
 SG_ PCS2_DRLog_CPU0_SampleRate_chann m119 : 8|8@1+ (1,0) [0|0] "" Vector__XXX
 SG_ PCS2_DRLog_CPU0_SampleRate_dcdc_ m163 : 8|8@1+ (1,0) [0|0] "" Vector__XXX
 SG_ PCS2_DRLog_CPU0_SampleRate__0003 m116 : 8|8@1+ (1,0) [0|0] "" Vector__XXX
 SG_ PCS2_DRLog_CPU0_SampleRate__0004 m102 : 8|8@1+ (1,0) [0|0] "" Vector__XXX
 SG_ PCS2_DRLog_CPU0_SampleRate__0000 m103 : 8|8@1+ (1,0) [0|0] "" Vector__XXX
 SG_ PCS2_DRLog_CPU0_SampleRate_freq m112 : 8|8@1+ (1,0) [0|0] "" Vector__XXX
 SG_ PCS2_DRLog_CPU0_SampleRate_half_ m113 : 8|8@1+ (1,0) [0|0] "" Vector__XXX
 SG_ PCS2_DRLog_CPU0_SampleRate__0007 m100 : 8|8@1+ (1,0) [0|0] "" Vector__XXX
 SG_ PCS2_DRLog_CPU0_SampleRate__0009 m115 : 8|8@1+ (1,0) [0|0] "" Vector__XXX
 SG_ PCS2_DRLog_CPU0_SampleRate__0012 m114 : 8|8@1+ (1,0) [0|0] "" Vector__XXX
 SG_ PCS2_DRLog_CPU0_SampleRate_i_HV_ m101 : 8|8@1+ (1,0) [0|0] "" Vector__XXX
 SG_ PCS2_DRLog_CPU0_SampleRate_itank m104 : 8|8@1+ (1,0) [0|0] "" Vector__XXX
 SG_ PCS2_DRLog_CPU0_SampleRate__0010 m109 : 8|8@1+ (1,0) [0|0] "" Vector__XXX
 SG_ PCS2_DRLog_CPU0_SampleRate_shrt_ m108 : 8|8@1+ (1,0) [0|0] "" Vector__XXX
 SG_ PCS2_DRLog_CPU0_SampleRate__0011 m107 : 8|8@1+ (1,0) [0|0] "" Vector__XXX
 SG_ PCS2_DRLog_CPU0_SampleRate_theta m110 : 8|8@1+ (1,0) [0|0] "" Vector__XXX
 SG_ PCS2_DRLog_CPU0_SampleRate__0001 m111 : 8|8@1+ (1,0) [0|0] "" Vector__XXX
 SG_ PCS2_DRLog_CPU0_SampleRate__0002 m105 : 8|8@1+ (1,0) [0|0] "" Vector__XXX
 SG_ PCS2_DRLog_CPU0_SampleRate_zcd_f m106 : 8|8@1+ (1,0) [0|0] "" Vector__XXX
 SG_ PCS2_DRLog_CPU0_SampleRate_zcd_r m165 : 8|8@1+ (1,0) [0|0] "" Vector__XXX
 SG_ PCS2_DRLog_CPU0_Version m1 : 8|8@1+ (1,0) [0|0] "" Vector__XXX
 SG_ PCS2_DRLog_CPU1_DlogClientConnec m13 : 8|1@1+ (1,0) [0|0] "" Vector__XXX
 SG_ PCS2_DRLog_CPU1_Postamble m14 : 8|56@1+ (1,0) [0|0] "" Vector__XXX
 SG_ PCS2_DRLog_CPU1_Preamble m10 : 8|56@1+ (1,0) [0|0] "" Vector__XXX
 SG_ PCS2_DRLog_CPU1_SampleRate m12 : 8|8@1+ (1,0) [0|0] "" Vector__XXX
 SG_ PCS2_DRLog_CPU1_SampleRate__0006 m138 : 8|8@1+ (1,0) [0|0] "" Vector__XXX
 SG_ PCS2_DRLog_CPU1_SampleRate_18V0_ m137 : 8|8@1+ (1,0) [0|0] "" Vector__XXX
 SG_ PCS2_DRLog_CPU1_SampleRate__0008 m161 : 8|8@1+ (1,0) [0|0] "" Vector__XXX
 SG_ PCS2_DRLog_CPU1_SampleRate_burst m159 : 8|8@1+ (1,0) [0|0] "" Vector__XXX
 SG_ PCS2_DRLog_CPU1_SampleRate_dcdc_ m139 : 8|8@1+ (1,0) [0|0] "" Vector__XXX
 SG_ PCS2_DRLog_CPU1_SampleRate__0000 m164 : 8|8@1+ (1,0) [0|0] "" Vector__XXX
 SG_ PCS2_DRLog_CPU1_SampleRate__0004 m123 : 8|8@1+ (1,0) [0|0] "" Vector__XXX
 SG_ PCS2_DRLog_CPU1_SampleRate__0005 m126 : 8|8@1+ (1,0) [0|0] "" Vector__XXX
 SG_ PCS2_DRLog_CPU1_SampleRate__0001 m127 : 8|8@1+ (1,0) [0|0] "" Vector__XXX
 SG_ PCS2_DRLog_CPU1_SampleRate_freq m136 : 8|8@1+ (1,0) [0|0] "" Vector__XXX
 SG_ PCS2_DRLog_CPU1_SampleRate_half_ m120 : 8|8@1+ (1,0) [0|0] "" Vector__XXX
 SG_ PCS2_DRLog_CPU1_SampleRate__0007 m124 : 8|8@1+ (1,0) [0|0] "" Vector__XXX
 SG_ PCS2_DRLog_CPU1_SampleRate__0009 m122 : 8|8@1+ (1,0) [0|0] "" Vector__XXX
 SG_ PCS2_DRLog_CPU1_SampleRate__0012 m121 : 8|8@1+ (1,0) [0|0] "" Vector__XXX
 SG_ PCS2_DRLog_CPU1_SampleRate_i_HV_ m125 : 8|8@1+ (1,0) [0|0] "" Vector__XXX
 SG_ PCS2_DRLog_CPU1_SampleRate_itank m128 : 8|8@1+ (1,0) [0|0] "" Vector__XXX
 SG_ PCS2_DRLog_CPU1_SampleRate__0010 m133 : 8|8@1+ (1,0) [0|0] "" Vector__XXX
 SG_ PCS2_DRLog_CPU1_SampleRate_shrt_ m132 : 8|8@1+ (1,0) [0|0] "" Vector__XXX
 SG_ PCS2_DRLog_CPU1_SampleRate__0011 m131 : 8|8@1+ (1,0) [0|0] "" Vector__XXX
 SG_ PCS2_DRLog_CPU1_SampleRate_theta m134 : 8|8@1+ (1,0) [0|0] "" Vector__XXX
 SG_ PCS2_DRLog_CPU1_SampleRate__0002 m135 : 8|8@1+ (1,0) [0|0] "" Vector__XXX
 SG_ PCS2_DRLog_CPU1_SampleRate__0003 m129 : 8|8@1+ (1,0) [0|0] "" Vector__XXX
 SG_ PCS2_DRLog_CPU1_SampleRate_zcd_f m130 : 8|8@1+ (1,0) [0|0] "" Vector__XXX
 SG_ PCS2_DRLog_CPU1_SampleRate_zcd_r m166 : 8|8@1+ (1,0) [0|0] "" Vector__XXX
 SG_ PCS2_DRLog_CPU1_Version m11 : 8|8@1+ (1,0) [0|0] "" Vector__XXX
 SG_ PCS2_DRLog_CPU2_DlogClientConnec m23 : 8|1@1+ (1,0) [0|0] "" Vector__XXX
 SG_ PCS2_DRLog_CPU2_Postamble m24 : 8|56@1+ (1,0) [0|0] "" Vector__XXX
 SG_ PCS2_DRLog_CPU2_Preamble m20 : 8|56@1+ (1,0) [0|0] "" Vector__XXX
 SG_ PCS2_DRLog_CPU2_SampleRate m22 : 8|8@1+ (1,0) [0|0] "" Vector__XXX
 SG_ PCS2_DRLog_CPU2_Version m21 : 8|8@1+ (1,0) [0|0] "" Vector__XXX
 SG_ PCS2_DRLog_CPU3_DlogClientConnec m33 : 8|1@1+ (1,0) [0|0] "" Vector__XXX
 SG_ PCS2_DRLog_CPU3_Postamble m34 : 8|56@1+ (1,0) [0|0] "" Vector__XXX
 SG_ PCS2_DRLog_CPU3_Preamble m30 : 8|56@1+ (1,0) [0|0] "" Vector__XXX
 SG_ PCS2_DRLog_CPU3_SampleRate m32 : 8|8@1+ (1,0) [0|0] "" Vector__XXX
 SG_ PCS2_DRLog_CPU3_SampleRate__0007 m157 : 8|8@1+ (1,0) [0|0] "" Vector__XXX
 SG_ PCS2_DRLog_CPU3_SampleRate_18V0_ m156 : 8|8@1+ (1,0) [0|0] "" Vector__XXX
 SG_ PCS2_DRLog_CPU3_SampleRate__0008 m162 : 8|8@1+ (1,0) [0|0] "" Vector__XXX
 SG_ PCS2_DRLog_CPU3_SampleRate_Itank m144 : 8|8@1+ (1,0) [0|0] "" Vector__XXX
 SG_ PCS2_DRLog_CPU3_SampleRate_freq m151 : 8|8@1+ (1,0) [0|0] "" Vector__XXX
 SG_ PCS2_DRLog_CPU3_SampleRate_hvdc_ m155 : 8|8@1+ (1,0) [0|0] "" Vector__XXX
 SG_ PCS2_DRLog_CPU3_SampleRate_i_ac_ m148 : 8|8@1+ (1,0) [0|0] "" Vector__XXX
 SG_ PCS2_DRLog_CPU3_SampleRate__0004 m149 : 8|8@1+ (1,0) [0|0] "" Vector__XXX
 SG_ PCS2_DRLog_CPU3_SampleRate__0005 m153 : 8|8@1+ (1,0) [0|0] "" Vector__XXX
 SG_ PCS2_DRLog_CPU3_SampleRate__0006 m147 : 8|8@1+ (1,0) [0|0] "" Vector__XXX
 SG_ PCS2_DRLog_CPU3_SampleRate_i_ln_ m142 : 8|8@1+ (1,0) [0|0] "" Vector__XXX
 SG_ PCS2_DRLog_CPU3_SampleRate__0000 m143 : 8|8@1+ (1,0) [0|0] "" Vector__XXX
 SG_ PCS2_DRLog_CPU3_SampleRate__0001 m154 : 8|8@1+ (1,0) [0|0] "" Vector__XXX
 SG_ PCS2_DRLog_CPU3_SampleRate_itank m150 : 8|8@1+ (1,0) [0|0] "" Vector__XXX
 SG_ PCS2_DRLog_CPU3_SampleRate_pwm_e m145 : 8|8@1+ (1,0) [0|0] "" Vector__XXX
 SG_ PCS2_DRLog_CPU3_SampleRate_v_dc m152 : 8|8@1+ (1,0) [0|0] "" Vector__XXX
 SG_ PCS2_DRLog_CPU3_SampleRate_v_ln_ m140 : 8|8@1+ (1,0) [0|0] "" Vector__XXX
 SG_ PCS2_DRLog_CPU3_SampleRate__0002 m141 : 8|8@1+ (1,0) [0|0] "" Vector__XXX
 SG_ PCS2_DRLog_CPU3_SampleRate__0003 m146 : 8|8@1+ (1,0) [0|0] "" Vector__XXX
 SG_ PCS2_DRLog_CPU3_SampleRate__0009 m167 : 8|8@1+ (1,0) [0|0] "" Vector__XXX
 SG_ PCS2_DRLog_CPU3_SampleRate__0010 m168 : 8|8@1+ (1,0) [0|0] "" Vector__XXX
 SG_ PCS2_DRLog_CPU3_Version m31 : 8|8@1+ (1,0) [0|0] "" Vector__XXX
 SG_ PCS2_DRLogIndex M : 0|8@1+ (1,0) [0|0] "" Vector__XXX

CM_ BO_ 2007 "ESP32-DualCAN Model3_VEH. Seen on this car: 8-byte frames; fit good (bits covered 100%, mux 100%, ranges 100%).";
VAL_ 2007 DI_regenBackfillAbsSatState 0 "IDLE" 1 "RAMP_OUT" 2 "RAMP_IN" ;
VAL_ 2007 DI_regenBackfillUnavailableReaso 0 "NONE" 1 "GTW_DISABLE" 2 "UI_DISABLE" 3 "EBR_UNAVAILABLE" 4 "CRUISE_ACTIVE" 5 "NON_DRIVE_GEAR" 6 "SYSTEM_STATE" 7 "UI_COASTDOWN_MODE" 8 "ACTIVE_DAMPING_UNAVAILABLE" 9 "TRACTION_CONTROL_UNAVAILABLE" 10 "VELOCITY_ESTIMATOR_UNAVAILABLE" 11 "TRACK_MODE_ACTIVE" 12 "PM_DISABLE_REQUEST" ;
VAL_ 2007 DI_debugSelector 2 "Mux2" 32 "pwrSat" 33 "Mux33" 34 "sysPedal" 35 "onePedalDriving1" 36 "onePedalDriving2" 37 "onePedalDriving3" 38 "pedalTorque1" 39 "regenBackfill" 45 "Mux45" 50 "sysHeat" 53 "Mux53" 65 "Mux65" 66 "Mux66" 67 "Mux67" 68 "Mux68" 69 "Mux69" 75 "longControl" ;
CM_ BO_ 2013 "ESP32-DualCAN Model3_VEH. Seen on this car: 5-byte frames; fit ok (bits covered 100%, mux 100%, ranges 100%).";
CM_ BO_ 2014 "ESP32-DualCAN Model3_VEH. Not seen on this car in the logs.";
CM_ BO_ 2015 "ESP32-DualCAN Model3_VEH. Not seen on this car in the logs.";
VAL_ 2015 UDS_functionalRequestData_0 0 "0" 1 "1" 2 "2" 3 "3" 4 "4" 5 "5" 6 "6" 7 "7" 8 "8" 9 "9" 10 "10" 11 "11" 12 "12" 13 "13" 14 "14" 15 "15" 16 "16" 17 "17" 18 "18" 19 "19" 20 "20" 21 "21" 22 "22" 23 "23" 24 "24" 25 "25" 26 "26" 27 "27" 28 "28" 29 "29" 30 "30" 31 "31" ;
CM_ BO_ 2019 "ESP32-DualCAN Model3_VEH. Not seen on this car in the logs.";
CM_ BO_ 2021 "ESP32-DualCAN Model3_VEH. Not seen on this car in the logs.";
CM_ BO_ 2031 "ESP32-DualCAN Model3_VEH. Not seen on this car in the logs.";
CM_ BO_ 2034 "ESP32-DualCAN Model3_VEH. Not seen on this car in the logs.";
VAL_ 2034 BMS_sleepState 0 "IDLE" 1 "WAIT_FOR_BUS_SILENCE" 2 "READY" 3 "GOING_TO_SLEEP" 4 "SLEEPING" 5 "ABORT" 6 "FAULT" 7 "MIA" 8 "UNKNOWN" 9 "COUNT" ;
VAL_ 2034 BMS_10HzDebug_Id 0 "STATE" 1 "AHR_COUNTER" 2 "ISOLATION" 3 "SOC_RESTING" 12 "THM_MODEL_DATA_9" 13 "THM_MODEL_DATA_10" 14 "THM_MODEL_DATA_11" 15 "PACK_VOLTAGES" 16 "HYST" 17 "CAC_1" 18 "CAC_2" 19 "CAC_3" 20 "WAKE_TIMERS" 21 "ADC_VREF" 22 "ADC_CP" 23 "ADC_DCLINK" 24 "ADC_MISC" 25 "ADC_FLOOD" 26 "POWER_PREDICTION_1" 27 "POWER_PREDICTION_2" 28 "POWER_PREDICTION_3" 29 "SLEEP_WAKE" 30 "STANDBY_SUPPLY" 31 "DRIVE_LIMITS" 32 "SOC_BY_AH" 33 "THM_TARGETS" ;
CM_ BO_ 2036 "ESP32-DualCAN Model3_VEH. Seen on this car: 1-byte frames; fit poor (bits covered 0%, mux 100%, ranges 100%).";
CM_ BO_ 2043 "ESP32-DualCAN Model3_VEH. Not seen on this car in the logs.";
VAL_ 2043 UI_debugDampingRequestRRR 255 "SNA" ;
VAL_ 2043 UI_debugDampingRequestRRC 255 "SNA" ;
VAL_ 2043 UI_debugDampingRequestRLR 255 "SNA" ;
VAL_ 2043 UI_debugDampingRequestRLC 255 "SNA" ;
VAL_ 2043 UI_debugDampingRequestFRR 255 "SNA" ;
VAL_ 2043 UI_debugDampingRequestFRC 255 "SNA" ;
VAL_ 2043 UI_debugDampingRequestFLR 255 "SNA" ;
VAL_ 2043 UI_debugDampingRequestFLC 255 "SNA" ;
CM_ BO_ 2046 "ESP32-DualCAN Model3_VEH. Not seen on this car in the logs.";
VAL_ 2046 PCS2_DRLog_CPU0_Sample_18V0_boos 127 "SNA" ;
VAL_ 2046 PCS2_DRLog_CPU0_Sample_18V0_buck 127 "SNA" ;
VAL_ 2046 PCS2_DRLog_CPU1_Sample_18V0_boos 127 "SNA" ;
VAL_ 2046 PCS2_DRLog_CPU3_Sample_18V0_boos 127 "SNA" ;
VAL_ 2046 PCS2_DRLog_CPU0_Index_18V0_boost 127 "SNA" ;
VAL_ 2046 PCS2_DRLog_CPU0_Index_18V0_buck_ 127 "SNA" ;
VAL_ 2046 PCS2_DRLog_CPU1_Index_18V0_boost 127 "SNA" ;
VAL_ 2046 PCS2_DRLog_CPU3_Index_18V0_boost 127 "SNA" ;
VAL_ 2046 PCS2_DRLog_CPU0_SampleRate__0008 127 "SNA" ;
VAL_ 2046 PCS2_DRLog_CPU0_SampleRate__0006 127 "SNA" ;
VAL_ 2046 PCS2_DRLog_CPU1_SampleRate__0008 127 "SNA" ;
VAL_ 2046 PCS2_DRLog_CPU3_SampleRate__0008 127 "SNA" ;
